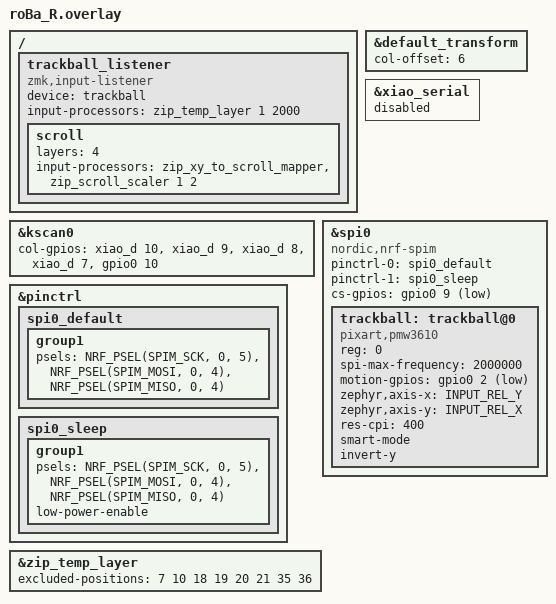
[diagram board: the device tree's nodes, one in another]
#include "roBa.dtsi"
#include <zephyr/dt-bindings/input/input-event-codes.h>
#include <input/processors.dtsi>

&default_transform {
    col-offset = <6>;
};

&kscan0 {
        col-gpios
            = <&xiao_d 10 GPIO_ACTIVE_HIGH>
            , <&xiao_d 9 GPIO_ACTIVE_HIGH>
            , <&xiao_d 8 GPIO_ACTIVE_HIGH>
            , <&xiao_d 7 GPIO_ACTIVE_HIGH>
            , <&gpio0 10 GPIO_ACTIVE_HIGH>
            ;
};

/ {
    trackball_listener {
        status = "okay";
        compatible = "zmk,input-listener";
        device = <&trackball>;
        
        // automouse-layer = <1> の代替: 移動時に指定時間レイヤー1を有効化
        input-processors = <&zip_temp_layer 1 2000>;
        
        // scroll-layers = <4> の代替: レイヤー4の時だけスクロールに変換し、さらに速度を1/2に落とす
        scroll {
            layers = <4>;
            input-processors = <&zip_xy_to_scroll_mapper>, <&zip_scroll_scaler 1 2>;
        };
    };
};

&pinctrl {
    spi0_default: spi0_default {
        group1 {
            psels = <NRF_PSEL(SPIM_SCK, 0, 5)>,
                <NRF_PSEL(SPIM_MOSI, 0, 4)>,
                <NRF_PSEL(SPIM_MISO, 0, 4)>;
        };
    };

    spi0_sleep: spi0_sleep {
        group1 {
            psels = <NRF_PSEL(SPIM_SCK, 0, 5)>,
                <NRF_PSEL(SPIM_MOSI, 0, 4)>,
                <NRF_PSEL(SPIM_MISO, 0, 4)>;
            low-power-enable;
        };
    };
};

&xiao_serial { status = "disabled"; };

&spi0 {
    status = "okay";
    compatible = "nordic,nrf-spim";
    pinctrl-0 = <&spi0_default>;
    pinctrl-1 = <&spi0_sleep>;
    pinctrl-names = "default", "sleep";
    cs-gpios = <&gpio0 9 GPIO_ACTIVE_LOW>;

    trackball: trackball@0 {
        status = "okay";
        compatible = "pixart,pmw3610";
        reg = <0>;
        spi-max-frequency = <2000000>;
        motion-gpios = <&gpio0 2 (GPIO_ACTIVE_LOW | GPIO_PULL_UP)>;     
        // scroll-layers = <4>; // Zephyr 4.1.0/ZMK native pointing requires zmk,input-listener for this
        zephyr,axis-x = <INPUT_REL_Y>;
        zephyr,axis-y = <INPUT_REL_X>;
        res-cpi = <400>;
        smart-mode;
        invert-y;
    };
};

&zip_temp_layer {
    // 7,18,19,20,35,36: マウス挙動
    // 10, 21: レイヤー4を呼び出すキー（&lt 4 C_SLEEP）
    // これらを押してもオートマウスレイヤーが解除されないようにする
    excluded-positions = <7 10 18 19 20 21 35 36>;
};
